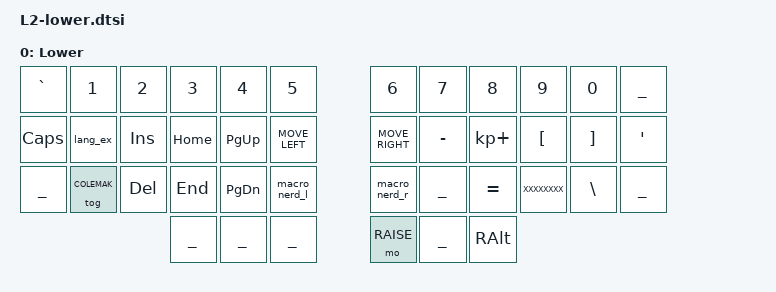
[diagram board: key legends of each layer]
/**
 *
 */

/ {
  keymap {
    compatible = "zmk,keymap";

	lower_layer {
		label = "Lower";
		bindings = <
// ╭───────────────┬───────────────┬───────────────┬───────────────┬───────────────┬───────────────╮   ╭───────────────┬───────────────┬───────────────┬───────────────┬───────────────┬───────────────╮
    &kp GRAVE     	&kp N1          &kp N2          &kp N3          &kp N4          &kp N5              &kp N6          &kp N7          &kp N8          &kp N9          &kp N0          ________
// ├───────────────├───────────────┼───────────────┼───────────────┼───────────────┼───────────────┤   ├───────────────├───────────────┼───────────────┼───────────────┼───────────────┼───────────────┤
	&kp CAPS        &lang_ex    	&kp INS       	&kp HOME        &kp PG_UP       MOVE_LEFT        	MOVE_RIGHT      &kp MINUS     	&kp KP_PLUS		&kp LBKT       	&kp RBKT        &kp SQT
// ├───────────────├───────────────┼───────────────┼───────────────┼───────────────┼───────────────┤   ├───────────────├───────────────┼───────────────┼───────────────┼───────────────┼───────────────┤
    ________      	&tog COLEMAK    &kp DEL        	&kp END        	&kp PG_DN       &macro_nerd_l		&macro_nerd_r   &kp UNDER  		&kp EQUAL       XXXXXXXX        &kp BSLH        ________
// ╰───────────────┴───────────────┴───────────────┼───────────────┼───────────────┼───────────────┤   ├───────────────├───────────────┼───────────────┼───────────────┴───────────────┴───────────────╯
                                    	            ________       	________        ________           	&mo RAISE		________		&kp	RALT
//                                                 ╰───────────────┴───────────────┴───────────────╯   ╰───────────────┴───────────────┴───────────────
			>;
		};
	};
};
